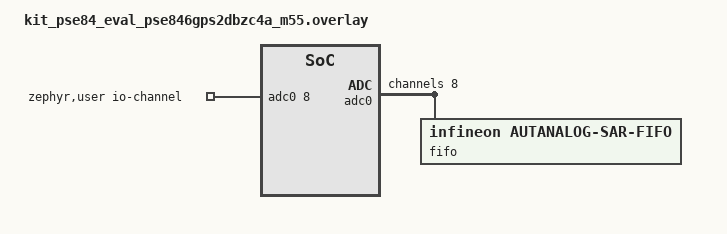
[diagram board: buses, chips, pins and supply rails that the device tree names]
/*
 * SPDX-FileCopyrightText: <text>Copyright (c) 2026 Infineon Technologies AG,
 * or an affiliate of Infineon Technologies AG. All rights reserved.</text>
 *
 * SPDX-License-Identifier: Apache-2.0
 */

#include <zephyr/dt-bindings/adc/adc.h>
#include <zephyr/dt-bindings/adc/infineon-autanalog-sar.h>
#include <dt-bindings/mfd/infineon-autanalog.h>

/ {
	aliases {
		adc0 = &adc0;
	};

	zephyr,user {
		io-channels = <&adc0 8>;
	};
};

&adc0 {
	status = "okay";
	#address-cells = <1>;
	#size-cells = <0>;

	/* Enable LP mode: clocked from LPOSC at 4.096 MHz, MUX channels only */
	lp-mode;

	/* MUX channel: P15.0 via internal MUX routing.
	 * Channel ID 8 = MUX channel index 0.
	 */
	channel@8 {
		reg = <8>;
		zephyr,acquisition-time = <ADC_ACQ_TIME(ADC_ACQ_TIME_MICROSECONDS, 250)>;
		zephyr,gain = "ADC_GAIN_1";
		zephyr,reference = "ADC_REF_INTERNAL";
		zephyr,resolution = <12>;
		zephyr,input-positive = <IFX_AUTANALOG_SAR_PIN_MUX_GPIO0>; /* P15.0 */
		fifo-sel = <IFX_AUTANALOG_SAR_FIFO_0>;
		mux-buf-bypass;
	};

	fifo {
		compatible = "infineon,autanalog-sar-fifo";
		fifo-levels = <256>;
	};
};
